# R40 register map
Vendor: Allwinner; Series: R40; File version: 0.1
CPU: CA7 0, little endian, MPU, FPU, double-precision FPU, 0 interrupt priority bits
Registers are 32-bit, read-write, reset 0x0 unless marked. A register's access mark holds for its fields unless they carry their own. Offsets are from the block's base; [hi:lo] are bit positions; {n}, {i} and the like mark numbered series; 'fields as' and 'values as' point back to an identical list; <NAME> marks a mode.

## SPI0
Base 0x01C05000
Same registers: SPI1 0x01C06000, SPI2 0x01C17000, SPI3 0x01C1F000
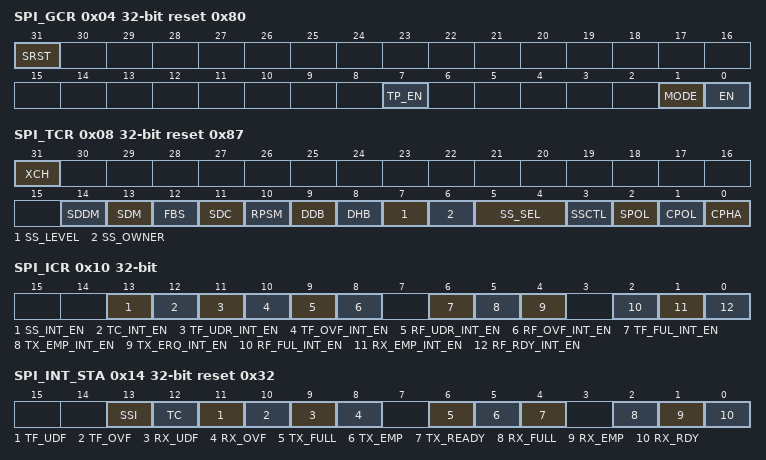
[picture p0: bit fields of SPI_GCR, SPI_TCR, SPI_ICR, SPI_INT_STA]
0x04 SPI_GCR reset 0x80 — SPI Global Control Register
  [31] SRST — Soft reset Writing `1` to this bit will clear the SPI controller, and automatically clear to `0` when reset operation completes. Writing `0` has no effect.
  [7] TP_EN — Transmit Pause Enable In master mode, it is used to control transmit state machine to stop smart burst sending when RX FIFO is full. 0 : Normal operation, ignore RXFIFO status 1 : Stop transmit data when RXFIFO full Note: Can not be written when XCH=1
  [1] MODE — SPI Function Mode Select 0: Slave Mode 1: Master Mode Note: Can not be written when XCH=1
    0=Slave Mode; 1=Master Mode Note: Can not be written when XCH=1
  [0] EN — SPI Module Enable Control 0: Disable 1: Enable
    0=Disable; 1=Enable
0x08 SPI_TCR reset 0x87 — SPI Transfer Control Register
  [31] XCH — Exchange Burst In master mode it is used to start SPI burst 0: Idle 1: Initiates exchange. Writing `1` to this bit will start the SPI burst, and will automatically clear after finishing the bursts transfer specified by . Writing `1` to will also clear this bit. Writing `0` to this bit has no effect.
    0=Idle; 1=Initiates exchange. Writing `1` to this bit will start the SPI burst, and will automatically clear after finishing the bursts transfer specified by . Writing `1` to will also clear this bit. Writing `0` to this bit has no effect.
  [14] SDDM — Sending Data Delay Mode 0: Normal sending 1: Delay sending Set the bit to"1" to make the data that should be sent with a delay of half cycle of SPI_CLK in dual IO mode for SPI mode 0.
    0=Normal sending; 1=Delay sending Set the bit to"1" to make the data that should be sent with a delay of half cycle of SPI_CLK in dual IO mode for SPI mode 0
  [13] SDM — Master Sample Data Mode 0: Delay Sample Mode 1: Normal Sample Mode In Normal Sample Mode, SPI master samples the data at the correct edge for each SPI mode; In Delay Sample Mode, SPI master samples data at the edge that is half cycle delayed by the correct edge defined in respective SPI mode.
    0=Delay Sample Mode; 1=Normal Sample Mode In Normal Sample Mode, SPI master samples the data at the correct edge for each SPI mode; In Delay Sample Mode, SPI master samples data at the edge that is half cycle delayed by the correct edge defined in respective SPI mode
  [12] FBS — First Transmit Bit Select 0: MSB first 1: LSB first
    0=MSB (MSB first); 1=LSB (LSB first)
  [11] SDC — Master Sample Data Control Set this bit to `1` to make the internal read sample point with a delay of half cycle of SPI_CLK. It is used in high speed read operation to reduce the error caused by the time delay of SPI_CLK propagating between master and slave. 0: Normal operation, do not delay internal read sample point 1: Delay internal read sample point
    0=Normal operation, do not delay internal read sample point; 1=Delay internal read sample point
  [10] RPSM — Rapids mode select Select Rapids mode for high speed write. 0: Normal write mode 1: Rapids write mode
    0=Normal write mode; 1=Rapids write mode
  [9] DDB — Dummy Burst Type 0: The bit value of dummy SPI burst is zero 1: The bit value of dummy SPI burst is one
    0=zero (The bit value of dummy SPI burst is zero); 1=one (The bit value of dummy SPI burst is one)
  [8] DHB — Discard Hash Burst In master mode it controls whether discarding unused SPI bursts. 0: Receiving all SPI bursts in BC period 1: Discard unused SPI bursts, only fetching the SPI bursts during dummy burst period. The bursts number is specified by TC.
    0=Receiving all SPI bursts in BC period; 1=Discard unused SPI bursts, only fetching the SPI bursts during dummy burst period. The bursts number is specified by TC.
  [7] SS_LEVEL — When control SS signal manually ( ==1), set this bit to `1` or `0` to control the level of SS signal. 0: Set SS to low 1: Set SS to high
    0=Set_SS_to_low; 1=Set_SS_to_high
  [6] SS_OWNER — SS Output Owner Select Usually, controller sends SS signal automatically with data together. When this bit is set to 1, software must manually write to 1 or 0 to control the level of SS signal. 0: SPI controller 1: Software
    0=SPI (SPI controller); 1=Software
  [5:4] SS_SEL — SPI Chip Select Select one of four external SPI Master/Slave Devices 00: SPI_SS0 will be asserted 01: SPI_SS1 will be asserted 10: SPI_SS2 will be asserted 11: SPI_SS3 will be asserted
    {v}=SPI_SS{v} (SPI_SS{v} will be asserted) (v=0..3)
  [3] SSCTL — In master mode, this bit selects the output wave form for the SPI_SSx signal. Only valid when = 0. 0: SPI_SSx remains asserted between SPI bursts 1: Negate SPI_SSx between SPI bursts
    0=SPI_SSx remains asserted between SPI bursts; 1=Negate SPI_SSx between SPI bursts
  [2] SPOL — SPI Chip Select Signal Polarity Control 0: Active high polarity (0 = Idle) 1: Active low polarity (1 = Idle)
    0=Active high polarity (0 = Idle); 1=Active low polarity (1 = Idle)
  [1] CPOL — SPI Clock Polarity Control 0: Active high polarity (0 = Idle) 1: Active low polarity (1 = Idle)
    values as SPOL
  [0] CPHA — SPI Clock/Data Phase Control 0: Phase 0 (Leading edge for sample data) 1: Phase 1 (Leading edge for setup data)
    0=Phase 0 (Leading edge for sample data); 1=Phase 1 (Leading edge for setup data)
0x10 SPI_ICR
  [all] fields
    0=Disable; 1=Enable
  [13] SS_INT_EN — SSI Interrupt Enable Chip Select Signal (SSx) from valid state to invalid state 0: Disable 1: Enable
  [12] TC_INT_EN — Transfer Completed Interrupt Enable 0: Disable 1: Enable
  [11] TF_UDR_INT_EN — TXFIFO Underrun Interrupt Enable 0: Disable 1: Enable
  [10] TF_OVF_INT_EN — TX FIFO Overflow Interrupt Enable 0: Disable 1: Enable
  [9] RF_UDR_INT_EN — RXFIFO Underrun Interrupt Enable 0: Disable 1: Enable
  [8] RF_OVF_INT_EN — RX FIFO Overflow Interrupt Enable 0: Disable 1: Enable
  [6] TF_FUL_INT_EN — TX FIFO Full Interrupt Enable 0: Disable 1: Enable
  [5] TX_EMP_INT_EN — TX FIFO Empty Interrupt Enable 0: Disable 1: Enable
  [4] TX_ERQ_INT_EN — TX FIFO Empty Request Interrupt Enable 0: Disable 1: Enable
  [2] RF_FUL_INT_EN — RX FIFO Full Interrupt Enable 0: Disable 1: Enable
  [1] RX_EMP_INT_EN — RX FIFO Empty Interrupt Enable 0: Disable 1: Enable
  [0] RF_RDY_INT_EN — RX FIFO Ready Request Interrupt Enable 0: Disable 1: Enable
0x14 SPI_INT_STA reset 0x32
  [13] SSI write-1-clears — SS Invalid Interrupt When SSI is 1, it indicates that SS has changed from valid state to invalid state. Writing 1 to this bit clears it.
  [12] TC write-1-clears — Transfer Completed In master mode, it indicates that all bursts specified by has been exchanged. In other condition, When set, this bit indicates that all the data in TXFIFO has been loaded in the shift register, and the shift register has shifted out all the bits. Writing 1 to this bit clears it. 0: Busy 1: Transfer Completed
    0=Busy; 1=Transfer Completed
  [11] TF_UDF write-1-clears — TXFIFO Underrun This bit is set when if the TXFIFO is underrun. Writing 1 to this bit clears it. 0: TXFIFO is not underrun 1: TXFIFO is underrun
    0=not_underrun (TXFIFO is not underrun); 1=underrun (TXFIFO is underrun)
  [10] TF_OVF write-1-clears — TXFIFO Overflow This bit is set when if the TXFIFO is overflow. Writing 1 to this bit clears it. 0: TXFIFO is not overflow 1: TXFIFO is overflowed
    0=not_overflow (TXFIFO is not overflow); 1=overflowed (TXFIFO is overflowed)
  [9] RX_UDF write-1-clears — RXFIFO Underrun When set, this bit indicates that RXFIFO has underrun. Writing 1 to this bit clears it.
  [8] RX_OVF write-1-clears — RXFIFO Overflow When set, this bit indicates that RXFIFO has overflowed. Writing 1 to this bit clears it. 0: RXFIFO is available. 1: RXFIFO has overflowed.
    0=available (RXFIFO is available.); 1=RXFIFO has overflowed
  [6] TX_FULL write-1-clears — TXFIFO Full This bit is set when if the TXFIFO is full . Writing 1 to this bit clears it. 0: TXFIFO is not Full 1: TXFIFO is Full
    0=not_Full (TXFIFO is not Full); 1=Full (TXFIFO is Full)
  [5] TX_EMP write-1-clears — TXFIFO Empty This bit is set if the TXFIFO is empty. Writing 1 to this bit clears it. 0: TXFIFO contains one or more words. 1: TXFIFO is empty
    0=TXFIFO contains one or more words; 1=empty (TXFIFO is empty)
  [4] TX_READY write-1-clears — TXFIFO Ready 0: TX_WL > TX_TRIG_LEVEL 1: TX_WL <= TX_TRIG_LEVEL This bit is set any time if TX_WL <= TX_TRIG_LEVEL. Writing `1` to this bit clears it. Where TX_WL is the water level of RXFIFO.
    0=TX_WL__gt_ (TX_WL > TX_TRIG_LEVEL); 1=TX_WL__lt__equals_ (TX_WL <= TX_TRIG_LEVEL This bit is set any time if TX_WL <= TX_TRIG_LEVEL. Writing `1` to this bit clears it. Where TX_WL is the water level of RXFIFO.)
  [2] RX_FULL write-1-clears — RXFIFO Full This bit is set when the RXFIFO is full . Writing 1 to this bit clears it. 0: Not Full 1: Full
    0=Not_Full; 1=Full
  [1] RX_EMP write-1-clears — RXFIFO Empty This bit is set when the RXFIFO is empty . Writing 1 to this bit clears it. 0: Not empty 1: empty
    0=Not_empty; 1=empty
  [0] RX_RDY write-1-clears — RXFIFO Ready 0: RX_WL < RX_TRIG_LEVEL 1: RX_WL >= RX_TRIG_LEVEL This bit is set any time if RX_WL >= RX_TRIG_LEVEL. Writing `1` to this bit clears it. Where RX_WL is the water level of RXFIFO.
    0=RX_WL__lt_ (RX_WL < RX_TRIG_LEVEL); 1=RX_WL__gt__equals_ (RX_WL >= RX_TRIG_LEVEL This bit is set any time if RX_WL >= RX_TRIG_LEVEL. Writing `1` to this bit clears it. Where RX_WL is the water level of RXFIFO.)
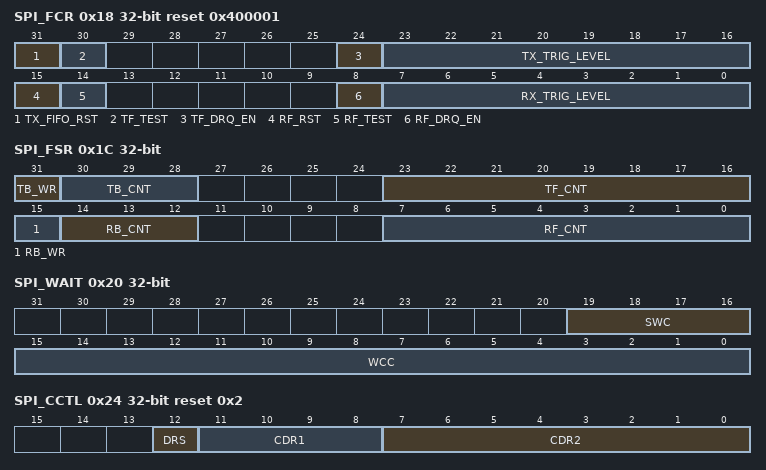
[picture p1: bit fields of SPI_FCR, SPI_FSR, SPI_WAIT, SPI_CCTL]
0x18 SPI_FCR reset 0x400001 — SPI FIFO Control Register
  [31] TX_FIFO_RST — TX FIFO Reset Writing `1` to this bit will reset the control portion of the TX FIFO and automatically clear to `0` when completing reset operation, writing to `0` has no effect.
  [30] TF_TEST — TX Test Mode Enable 0: Disable 1: Enable In normal mode, TX FIFO can only be read by SPI controller, writing `1` to this bit will switch TX FIFO read and write function to AHB bus. This bit is used to test the TX FIFO. and can not be set at the same time.
    0=Disable; 1=Enable In normal mode, TX FIFO can only be read by SPI controller, writing `1` to this bit will switch TX FIFO read and write function to AHB bus. This bit is used to test the TX FIFO. and can not be set at the same time.
  [24] TF_DRQ_EN — TX FIFO DMA Request Enable 0: Disable 1: Enable
    0=Disable; 1=Enable
  [23:16] TX_TRIG_LEVEL — TX FIFO Empty Request Trigger Level
  [15] RF_RST — RXFIFO Reset Writing `1` to this bit will reset the control portion of the receiver FIFO, and auto clear to `0` when completing reset operation, writing `0` to this bit has no effect.
  [14] RF_TEST — RX Test Mode Enable 0: Disable 1: Enable In normal mode, RX FIFO can only be written by SPI controller, write `1` to this bit will switch RX FIFO read and write function to AHB bus. This bit is used to test the RX FIFO. and can not be set at the same time.
    0=Disable; 1=Enable In normal mode, RX FIFO can only be written by SPI controller, write `1` to this bit will switch RX FIFO read and write function to AHB bus. This bit is used to test the RX FIFO. and can not be set at the same time.
  [8] RF_DRQ_EN — RX FIFO DMA Request Enable 0: Disable 1: Enable
    0=Disable; 1=Enable
  [7:0] RX_TRIG_LEVEL — RX FIFO Ready Request Trigger Level
0x1C SPI_FSR — SPI FIFO Status Register
  [31] TB_WR ro — TX FIFO Write Buffer Write Enable
  [30:28] TB_CNT ro — TX FIFO Write Buffer Counter These bits indicate the number of words in TX FIFO Write Buffer
  [23:16] TF_CNT ro — TX FIFO Counter These bits indicate the number of words in TX FIFO. 00000000: 0 byte in TX FIFO 00000001: 1 byte in TX FIFO ... 01000000: 64 bytes in TX FIFO Others:Reserved
    0=0 byte in TX FIFO; 1=1 byte in TX FIFO ; 64=64 bytes in TX FIFO Others:Reserved
  [15] RB_WR ro — RX FIFO Read Buffer Write Enable
  [14:12] RB_CNT ro — RX FIFO Read Buffer Counter These bits indicate the number of words in RX FIFO Read Buffer
  [7:0] RF_CNT ro — RX FIFO Counter These bits indicate the number of words in RX FIFO 00000000: 0 byte in RX FIFO 00000001: 1 byte in RX FIFO ... 01000000:64 bytes in RX FIFO Others:Reserved
    0=0 byte in RX FIFO; 1=1 byte in RX FIFO ... 01000000:64 bytes in RX FIFO Others:Reserved
0x20 SPI_WAIT
  [19:16] SWC — Dual mode direction switch wait clock counter (for master mode only). 0: No wait states inserted N: N SPI_SCLK wait states inserted These bits control the number of wait states to be inserted before start dual data transfer in dual SPI mode. The SPI module counts SPI_SCLK by for delaying next word data transfer. Note Can not be written when XCH=1.
  [15:0] WCC — Wait Clock Counter (In Master mode) 0: No wait states inserted N: N SPI_SCLK wait states inserted These bits control the number of wait states to be inserted in data transfers. The SPI module counts SPI_SCLK by for delaying next word data transfer.
0x24 SPI_CCTL reset 0x2
  [12] DRS — Divide Rate Select (Master Mode Only) 0: Select Clock Divide Rate 1 1: Select Clock Divide Rate 2
    0=Select_Clock_Divide_Rate_1; 1=Select_Clock_Divide_Rate_2
  [11:8] CDR1 — Clock Divide Rate 1 (Master Mode Only) The SPI_SCLK is determined according to the following equation: SPI_CLK = Source_CLK / 2^n.
  [7:0] CDR2 — Clock Divide Rate 2 (Master Mode Only) The SPI_SCLK is determined according to the following equation: SPI_CLK = Source_CLK / (2*(n + 1)).
0x30 SPI_BC
  [23:0] MBC — Master Burst Counter In master mode, this field specifies the total burst number. 0: 0 burst 1: 1 burst ... N: N bursts
0x34 SPI_TC
  [23:0] MWTC — Master Write Transmit Counter In master mode, this field specifies the burst number that should be sent to TXFIFO before automatically sending dummy burst. For saving bus bandwidth, the dummy burst (all zero bits or all one bits) is sent by SPI Controller automatically. 0: 0 burst 1: 1 burst ... N: N bursts
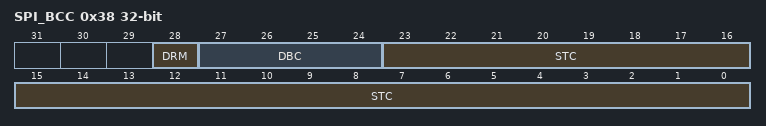
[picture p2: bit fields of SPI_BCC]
0x38 SPI_BCC — SPI Burst Control Register
  [28] DRM — Master Dual Mode RX Enable 0: RX use single-bit mode 1: RX use dual mode
    0=RX use single-bit mode; 1=RX use dual mode
  [27:24] DBC — Master Dummy Burst Counter In master mode, this field specifies the burst number that should be sent before receive in dual SPI mode. The device does not care the data. 0: 0 burst 1: 1 burst ... N: N bursts
  [23:0] STC — Master Single Mode Transmit Counter In master mode, this field specifies the burst number that should be sent in single mode before automatically sending dummy burst. This is the first transmit counter in all bursts. 0: 0 burst 1: 1 burst ... N: N bursts
0x88 SPI_NDMA_MODE_CTL reset 0xA5 — SPI Normal DMA Mode Control Register
  [7:0] NDMA_MODE_CTL — 0xEA:NDMA handshake mode Note: NDMA wait mode don't care this value.0xA5 can be used in handshake mode, but 0xEA is better.
0x200 SPI_TXD — SPI TX Data Register
  [31:0] TDATA — Transmit Data This register can be accessed in byte, half-word or word unit by AHB. In byte accessing method, if there are rooms in RXFIFO, one burst data is written to RXFIFO and the depth is increased by 1. In half-word accessing method, two SPI burst data are written and the TXFIFO depth is increase by 2. In word accessing method, four SPI burst data are written and the TXFIFO depth is increased by 4. Note: This address is writing-only if is `0`, and if is set to `1`, this address is readable and writable to test the TX FIFO through the AHB bus.
0x300 SPI_RXD — SPI RX Data Register
  [31:0] RDATA ro — Receive Data This register can be accessed in byte, half-word or word unit by AHB. In byte accessing method, if there are data in RXFIFO, the top word is returned and the RXFIFO depth is decreased by 1. In half-word accessing method, two SPI bursts are returned and the RXFIFO depth is decrease by 2. In word accessing method, the four SPI bursts are returned and the RXFIFO depth is decreased by 4. Note: This address is read-only if is `0`, and if is set to `1`, this address is readable and writable to test the RX FIFO through the AHB bus.
